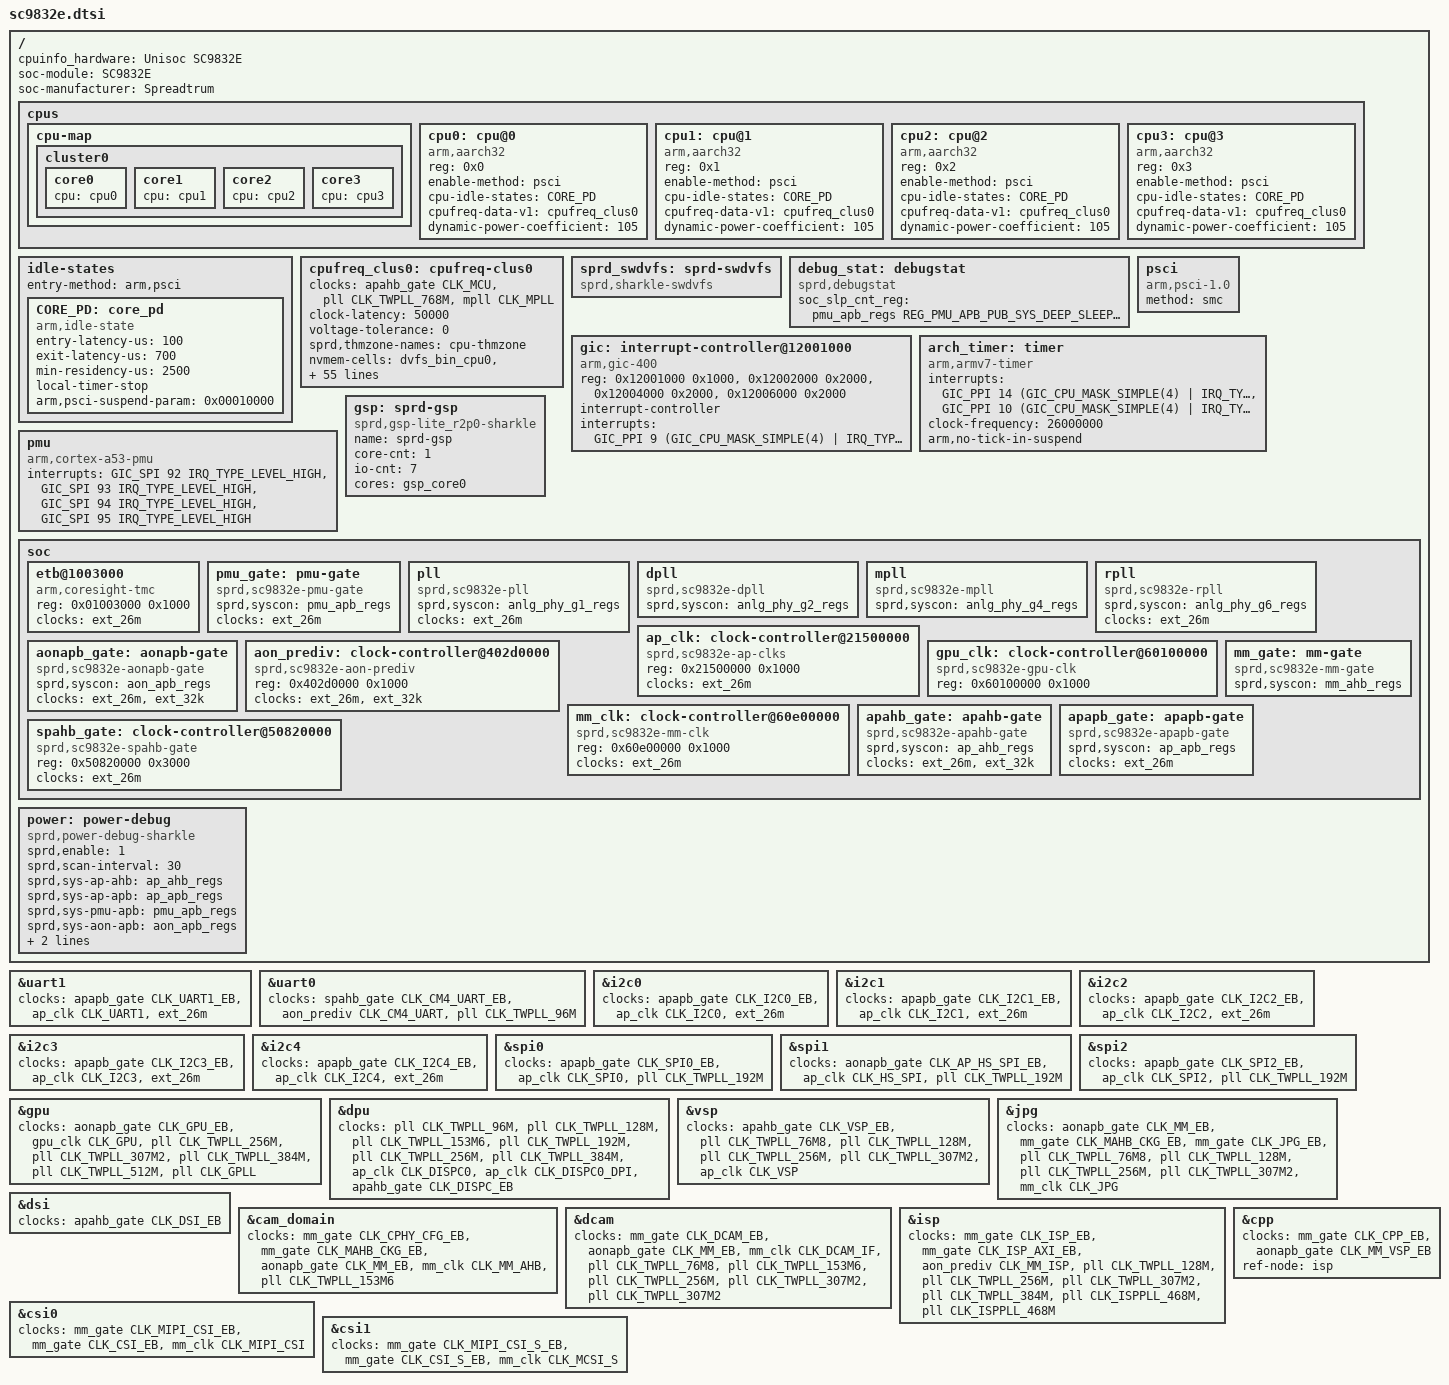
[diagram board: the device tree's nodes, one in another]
// SPDX-License-Identifier: GPL-2.0-only
/*
 * Spreadtrum SC9832e SoC DTS file
 *
 * Copyright (C) 2021, Spreadtrum Communications Inc.
 *
 * This file is licensed under a dual GPLv2 or X11 license.
 */
#include <dt-bindings/clock/sprd,sc9832e-clk.h>
#include "sharkle.dtsi"

/ {
	cpuinfo_hardware = "Unisoc SC9832E";
	soc-module = "SC9832E";
	soc-manufacturer = "Spreadtrum";

	cpus {
		#address-cells = <1>;
		#size-cells = <0>;

		cpu-map {
			cluster0 {
				core0 {
					cpu = <&cpu0>;
				};
				core1 {
					cpu = <&cpu1>;
				};
				core2 {
					cpu = <&cpu2>;
				};
				core3 {
					cpu = <&cpu3>;
				};
			};
		};


		cpu0: cpu@0 {
			device_type = "cpu";
			compatible = "arm,aarch32";
			reg = <0x0>;
			enable-method = "psci";
			cpu-idle-states = <&CORE_PD>;
			cpufreq-data-v1 = <&cpufreq_clus0>;
			dynamic-power-coefficient = <105>;
			#cooling-cells = <2>;
		};
		cpu1: cpu@1 {
			device_type = "cpu";
			compatible = "arm,aarch32";
			reg = <0x1>;
			enable-method = "psci";
			cpu-idle-states = <&CORE_PD>;
			cpufreq-data-v1 = <&cpufreq_clus0>;
			dynamic-power-coefficient = <105>;
			#cooling-cells = <2>;
		};
		cpu2: cpu@2 {
			device_type = "cpu";
			compatible = "arm,aarch32";
			reg = <0x2>;
			enable-method = "psci";
			cpu-idle-states = <&CORE_PD>;
			cpufreq-data-v1 = <&cpufreq_clus0>;
			dynamic-power-coefficient = <105>;
			#cooling-cells = <2>;
		};
		cpu3: cpu@3 {
			device_type = "cpu";
			compatible = "arm,aarch32";
			reg = <0x3>;
			enable-method = "psci";
			cpu-idle-states = <&CORE_PD>;
			cpufreq-data-v1 = <&cpufreq_clus0>;
			dynamic-power-coefficient = <105>;
			#cooling-cells = <2>;
		};
	};

	idle-states{
		entry-method = "arm,psci";
		CORE_PD: core_pd {
			compatible = "arm,idle-state";
			entry-latency-us = <100>;
			exit-latency-us = <700>;
			min-residency-us = <2500>;
			local-timer-stop;
			arm,psci-suspend-param = <0x00010000>;
		};
	};

	cpufreq_clus0: cpufreq-clus0 {
		clocks = <&apahb_gate CLK_MCU>,
			<&pll CLK_TWPLL_768M>,
			<&mpll CLK_MPLL>;
		clock-names = "core_clk",
			"low_freq_clk_parent",
			"high_freq_clk_parent";
		clock-latency = <50000>;
		voltage-tolerance = <0>;
		sprd,thmzone-names = "cpu-thmzone";
		nvmem-cells = <&dvfs_bin_cpu0>, <&dvfs_bin_low_volt_cpu0>;
		nvmem-cell-names = "dvfs_bin", "dvfs_bin_low_volt";
		sprd,cpufreq-temp-threshold = <65>;
		cpufreq-cluster-cpumask = <0xf>;
		sprd,ss-waferid-names =
			"T8F619_1","T8F619_2",
			"T8F619_3","T8F619_4",
			"T8F619_6","T8F619_7",
			"T8F619_8","T8F619_10",
			"T8F619_11","T8F619_12",
			"T8F619_13","T8F619_15",
			"T8F619_16","T8F619_18",
			"T8F619_19","T8F619_20",
			"T8F619_22","T8F619_23",
			"T8F619_24","T8F619_25",
			"T8F622_1","T8F622_2",
			"T8F622_3","T8F622_4",
			"T8F622_5","T8F622_6",
			"T8F801_1","T8F801_2",
			"T8F801_4","T8F801_3",
			"T9S964_1";
		operating-points = <
			/* kHz  uV */
			1400000 1150000
			1300000 1112500
			1100000 1034375
			 900000 953125
			 768000 900000>;
		operating-points-1-0 = <
			/* kHz	uV */
			/*1500000 1056250*/
			1400000	1021875
			1300000	 987500
			1100000	 918750
			 900000	 900000
			 768000	 900000>;
		operating-points-2-0 = <
			/* kHz	uV */
			/*1500000 1109375*/
			1400000	1071875
			1300000	1034375
			1100000	 959375
			 900000	 900000
			 768000	 900000>;
		operating-points-3-0 = <
			/* kHz	uV */
			1400000	1121875
			1300000	1081250
			1100000	1000000
			 900000	 921875
			 768000	 900000>;
		operating-points-4-0 = <
			/* kHz	uV */
			1400000	1150000
			1300000	1112500
			1100000	1034375
			 900000	 953125
			 768000	 900000>;
		operating-points-1-1 = <
			/* kHz	uV */
			/*1500000 1056250*/
			1400000	1021875
			1300000	 987500
			1100000	 918750
			 900000	 850000
			 768000	 850000>;
		operating-points-2-1 = <
			/* kHz	uV */
			/*1500000 1109375*/
			1400000	1071875
			1300000	1034375
			1100000	 959375
			 900000	 881250
			 768000	 850000>;
		operating-points-3-1 = <
			/* kHz	uV */
			1400000	1121875
			1300000	1081250
			1100000	1000000
			 900000	 921875
			 768000	 868750>;
		operating-points-4-1 = <
			/* kHz	uV */
			1400000	1150000
			1300000	1112500
			1100000	1034375
			 900000	 953125
			 768000	 900000>;
		operating-points-1-0-65 = <
			/* kHz	uV */
			/*1500000 1084375*/
			1400000	1043750
			1300000	1003125
			1100000	 921875
			 900000	 900000
			 768000	 900000>;
		operating-points-2-0-65 = <
			/* kHz	uV */
			/*1500000 1140625*/
			1400000	1096875
			1300000	1053125
			1100000	 965625
			 900000	 900000
			 768000	 900000>;
		operating-points-3-0-65 = <
			/* kHz	uV */
			1400000	1150000
			1300000	1106250
			1100000	1015625
			 900000	 925000
			 768000	 900000>;
		operating-points-4-0-65 = <
			/* kHz	uV */
			/*1400000 1181250*/
			1300000	1137500
			1100000	1050000
			 900000	 959375
			 768000	 900000>;
		operating-points-1-1-65 = <
			/* kHz	uV */
			/*1500000 1084375*/
			1400000	1043750
			1300000	1003125
			1100000	 921875
			 900000	 900000
			 768000	 900000>;
		operating-points-2-1-65 = <
			/* kHz	uV */
			/*1500000 1140625*/
			1400000	1096875
			1300000	1053125
			1100000	 965625
			 900000	 900000
			 768000	 900000>;
		operating-points-3-1-65 = <
			/* kHz	uV */
			1400000	1150000
			1300000	1106250
			1100000	1015625
			 900000	 925000
			 768000	 900000>;
		operating-points-4-1-65 = <
			/* kHz	uV */
			/*1400000 1181250*/
			1300000	1137500
			1100000	1050000
			 900000	 959375
			 768000	 900000>;
		operating-points-3 = <
			/* kHz	uV */
			1400000	1121875
			1300000	1081250
			1100000	1000000
			 900000	 921875
			 768000	 900000>;
		operating-points-4 = <
			/* kHz	uV */
			1400000	1150000
			1300000	1112500
			1100000	1034375
			 900000	 953125
			 768000	 900000>;
		operating-points-3-65 = <
			/* kHz	uV */
			1400000	1150000
			1300000	1106250
			1100000	1015625
			 900000	 925000
			 768000	 900000>;
		operating-points-4-65 = <
			/* kHz	uV */
			/*1400000 1181250*/
			1300000	1137500
			1100000	1050000
			 900000	 959375
			 768000	 900000>;
	};

	sprd_swdvfs: sprd-swdvfs {
		compatible = "sprd,sharkle-swdvfs";
	};

	debug_stat: debugstat {
		compatible = "sprd,debugstat";
		soc_slp_cnt_reg = <&pmu_apb_regs REG_PMU_APB_PUB_SYS_DEEP_SLEEP_CNT 0xff>;
	};

	psci {
		compatible = "arm,psci-1.0";
		method = "smc";
	};

	gic: interrupt-controller@12001000 {
		compatible = "arm,gic-400";
		reg = <0x12001000 0x1000>,
			<0x12002000 0x2000>,
			<0x12004000 0x2000>,
			<0x12006000 0x2000>;
		#interrupt-cells = <3>;
		interrupt-controller;
		interrupts = <GIC_PPI 9 (GIC_CPU_MASK_SIMPLE(4) | IRQ_TYPE_LEVEL_HIGH)>;
	};

	arch_timer: timer {
		compatible = "arm,armv7-timer";
		interrupts = <GIC_PPI 14 (GIC_CPU_MASK_SIMPLE(4) | IRQ_TYPE_LEVEL_LOW)>,
			     <GIC_PPI 10 (GIC_CPU_MASK_SIMPLE(4) | IRQ_TYPE_LEVEL_LOW)>;
		clock-frequency = <26000000>;
		arm,no-tick-in-suspend;
	};

	pmu {
		compatible = "arm,cortex-a53-pmu";
		interrupts = <GIC_SPI 92 IRQ_TYPE_LEVEL_HIGH>,
				<GIC_SPI 93 IRQ_TYPE_LEVEL_HIGH>,
				<GIC_SPI 94 IRQ_TYPE_LEVEL_HIGH>,
				<GIC_SPI 95 IRQ_TYPE_LEVEL_HIGH>;
	};

	gsp: sprd-gsp {
		compatible = "sprd,gsp-lite_r2p0-sharkle";
		name = "sprd-gsp";
		core-cnt = <1>;
		io-cnt = <7>;
		cores = <&gsp_core0>;
	};

	soc {
		etb@1003000 {
			compatible = "arm,coresight-tmc", "arm,primecell";
			reg = <0x01003000 0x1000>;
			clocks = <&ext_26m>;
			clock-names = "apb_pclk";
		};

		pmu_gate: pmu-gate {
			compatible = "sprd,sc9832e-pmu-gate";
			sprd,syscon = <&pmu_apb_regs>; /* 0x402b0000 */
			clock-names = "ext-26m";
			clocks = <&ext_26m>;
			#clock-cells = <1>;
		};

		pll: pll {
			compatible = "sprd,sc9832e-pll";
			sprd,syscon = <&anlg_phy_g1_regs>; /* 0x403c0000 */
			clock-names = "ext-26m";
			clocks = <&ext_26m>;
			#clock-cells = <1>;
		};

		dpll: dpll {
			compatible = "sprd,sc9832e-dpll";
			sprd,syscon = <&anlg_phy_g2_regs>; /* 0x403d0000 */
			#clock-cells = <1>;
		};

		mpll: mpll {
			compatible = "sprd,sc9832e-mpll";
			sprd,syscon = <&anlg_phy_g4_regs>; /* 0x403f0000 */
			#clock-cells = <1>;
		};

		rpll: rpll {
			compatible = "sprd,sc9832e-rpll";
			sprd,syscon = <&anlg_phy_g6_regs>; /* 0x40410000 */
			clock-names = "ext-26m";
			clocks = <&ext_26m>;
			#clock-cells = <1>;
		};

		ap_clk: clock-controller@21500000 {
			compatible = "sprd,sc9832e-ap-clks"; /* 0x21500000 */
			reg = <0x21500000 0x1000>;
			clock-names = "ext-26m";
			clocks = <&ext_26m>;
			#clock-cells = <1>;
		};

		aonapb_gate: aonapb-gate {
			compatible = "sprd,sc9832e-aonapb-gate"; /* 0x402e0000 */
			sprd,syscon = <&aon_apb_regs>;
			clock-names = "ext-26m", "ext-32k";
			clocks = <&ext_26m>, <&ext_32k>;
			#clock-cells = <1>;
		};

		aon_prediv: clock-controller@402d0000 {
			compatible = "sprd,sc9832e-aon-prediv"; /* 0x402d0000 */
			reg = <0x402d0000 0x1000>;
			clock-names = "ext-26m", "ext-32k";
			clocks = <&ext_26m>, <&ext_32k>;
			#clock-cells = <1>;
		};

		gpu_clk: clock-controller@60100000 {
			compatible = "sprd,sc9832e-gpu-clk";
			reg = <0x60100000 0x1000>; /* 0x60100000 */
			#clock-cells = <1>;
		};

		mm_clk: clock-controller@60e00000 {
			compatible = "sprd,sc9832e-mm-clk";
			reg = <0x60e00000 0x1000>; /* 0x60e00000 */
			clock-names = "ext-26m";
			clocks = <&ext_26m>;
			#clock-cells = <1>;
		};

		mm_gate: mm-gate {
			compatible = "sprd,sc9832e-mm-gate";
			sprd,syscon = <&mm_ahb_regs>; /* 0x60d00000 */
			#clock-cells = <1>;
		};

		apahb_gate: apahb-gate {
			compatible = "sprd,sc9832e-apahb-gate";
			sprd,syscon = <&ap_ahb_regs>; /* 0x20e00000 */
			clock-names = "ext-26m", "ext-32k";
			clocks = <&ext_26m>, <&ext_32k>;
			#clock-cells = <1>;
		};

		apapb_gate: apapb-gate {
			compatible = "sprd,sc9832e-apapb-gate";
			sprd,syscon = <&ap_apb_regs>; /* 0x71300000 */
			clock-names = "ext-26m";
			clocks = <&ext_26m>;
			#clock-cells = <1>;
			#reset-cells = <1>;
		};

		spahb_gate: clock-controller@50820000 {
			compatible = "sprd,sc9832e-spahb-gate";
			reg = <0x50820000 0x3000>; /* 0x50820000 */
			clock-names = "ext-26m";
			clocks = <&ext_26m>;
			#clock-cells = <1>;
		};
	};

	power: power-debug {
		compatible = "sprd,power-debug-sharkle";

		sprd,enable = <1>;
		sprd,scan-interval = <30>;

		sprd,sys-ap-ahb = <&ap_ahb_regs>;
		sprd,sys-ap-apb = <&ap_apb_regs>;
		sprd,sys-pmu-apb = <&pmu_apb_regs>;
		sprd,sys-aon-apb = <&aon_apb_regs>;
		sprd,sys-ap-intc = <&intc0_regs &intc1_regs
				&intc2_regs &intc3_regs>;
	};
};

&uart1 {
	clock-names = "enable", "uart", "source";
	clocks = <&apapb_gate CLK_UART1_EB>,
		 <&ap_clk CLK_UART1>, <&ext_26m>;
};

&uart0 {
	clock-names = "enable", "uart", "source";
	clocks = <&spahb_gate CLK_CM4_UART_EB>,
		 <&aon_prediv CLK_CM4_UART>, <&pll CLK_TWPLL_96M>;
};

&i2c0 {
	clock-names ="enable", "i2c", "source";
	clocks = <&apapb_gate CLK_I2C0_EB>,
	<&ap_clk CLK_I2C0>, <&ext_26m>;
};

&i2c1 {
	clock-names ="enable", "i2c", "source";
	clocks = <&apapb_gate CLK_I2C1_EB>,
	<&ap_clk CLK_I2C1>, <&ext_26m>;
};

&i2c2 {
	clock-names ="enable", "i2c", "source";
	clocks = <&apapb_gate CLK_I2C2_EB>,
	<&ap_clk CLK_I2C2>, <&ext_26m>;
};

&i2c3 {
	clock-names ="enable", "i2c", "source";
	clocks = <&apapb_gate CLK_I2C3_EB>,
	<&ap_clk CLK_I2C3>, <&ext_26m>;
};

&i2c4 {
	clock-names ="enable", "i2c", "source";
	clocks = <&apapb_gate CLK_I2C4_EB>,
	<&ap_clk CLK_I2C4>, <&ext_26m>;
};


&spi0 {
	clock-names ="enable", "spi", "source";
	clocks = <&apapb_gate CLK_SPI0_EB>,
	<&ap_clk CLK_SPI0>, <&pll CLK_TWPLL_192M>;
};

&spi1 {
	clock-names ="enable", "spi", "source";
	clocks = <&aonapb_gate CLK_AP_HS_SPI_EB>,
	<&ap_clk CLK_HS_SPI>, <&pll CLK_TWPLL_192M>;
};

&spi2 {
	clock-names ="enable", "spi", "source";
	clocks = <&apapb_gate CLK_SPI2_EB>,
	<&ap_clk CLK_SPI2>, <&pll CLK_TWPLL_192M>;
};

&gpu {
	clocks = <&aonapb_gate CLK_GPU_EB>,
		<&gpu_clk CLK_GPU>,
		<&pll CLK_TWPLL_256M>, <&pll CLK_TWPLL_307M2>,
		<&pll CLK_TWPLL_384M>, <&pll CLK_TWPLL_512M>,
		<&pll CLK_GPLL>;
};

&dpu {
	clock-names = "clk_src_96m",
			"clk_src_128m",
			"clk_src_153m6",
			"clk_src_192m",
			"clk_src_256m",
			"clk_src_384m",
			"clk_dpu_core",
			"clk_dpu_dpi",
			"clk_ap_ahb_disp_eb";

	clocks = <&pll CLK_TWPLL_96M>,
		<&pll CLK_TWPLL_128M>,
		<&pll CLK_TWPLL_153M6>,
		<&pll CLK_TWPLL_192M>,
		<&pll CLK_TWPLL_256M>,
		<&pll CLK_TWPLL_384M>,
		<&ap_clk CLK_DISPC0>,
		<&ap_clk CLK_DISPC0_DPI>,
		<&apahb_gate CLK_DISPC_EB>;
};

&vsp {
	clock-names = "clk_ahb_gate_vsp_eb",
			"clk_src_76m8",
			"clk_src_128m",
			"clk_src_256m",
			"clk_src_307m2",
			"clk_vsp";
	clocks = <&apahb_gate CLK_VSP_EB>,
		<&pll CLK_TWPLL_76M8>,
		<&pll CLK_TWPLL_128M>,
		<&pll CLK_TWPLL_256M>,
		<&pll CLK_TWPLL_307M2>,
		<&ap_clk CLK_VSP>;
};

&jpg {
	clock-names =
			"jpg_domain_eb",
			"jpg_ckg_eb",
			"jpg_dev_eb",
			"clk_src_76m8",
			"clk_src_128m",
			"clk_src_256m",
			"clk_src_307m2",
			"jpg_clk";
	clocks = <&aonapb_gate CLK_MM_EB>,
		<&mm_gate CLK_MAHB_CKG_EB>,
		<&mm_gate CLK_JPG_EB>,
		<&pll CLK_TWPLL_76M8>,
		<&pll CLK_TWPLL_128M>,
		<&pll CLK_TWPLL_256M>,
		<&pll CLK_TWPLL_307M2>,
		<&mm_clk CLK_JPG>;
};

&dsi {
	clock-names = "clk_ap_ahb_dsi_eb";
	clocks = <&apahb_gate CLK_DSI_EB>;
};

&cam_domain {
	clock-names = "clk_cphy_cfg_gate_eb",
				"clk_gate_eb",
				"clk_mm_eb",
				"clk_mm_ahb",
				"clk_mm_ahb_parent";
	clocks = <&mm_gate CLK_CPHY_CFG_EB>,
				<&mm_gate CLK_MAHB_CKG_EB>,
				<&aonapb_gate CLK_MM_EB>,
				<&mm_clk CLK_MM_AHB>,
				<&pll CLK_TWPLL_153M6>;
};

&dcam {
	clock-names = "dcam_eb",
			"clk_mm_eb",
			"dcam_clk",
			"dcam_clk_76m8",
			"dcam_clk_153m6",
			"dcam_clk_256m",
			"dcam_clk_307m2",
			"dcam_clk_parent";
	clocks = <&mm_gate CLK_DCAM_EB>,
		<&aonapb_gate CLK_MM_EB>,
		<&mm_clk CLK_DCAM_IF>,
		<&pll CLK_TWPLL_76M8>,
		<&pll CLK_TWPLL_153M6>,
		<&pll CLK_TWPLL_256M>,
		<&pll CLK_TWPLL_307M2>,
		<&pll CLK_TWPLL_307M2>;
};

&isp {
	clock-names = "isp_eb", "isp_axi_eb",
			"isp_clk",
			"isp_clk_128m",
			"isp_clk_256m",
			"isp_clk_307m2",
			"isp_clk_384m",
			"isp_clk_468m",
			"isp_clk_parent";
	clocks = <&mm_gate CLK_ISP_EB>,
		<&mm_gate CLK_ISP_AXI_EB>,
		<&aon_prediv CLK_MM_ISP>,
		<&pll CLK_TWPLL_128M>,
		<&pll CLK_TWPLL_256M>,
		<&pll CLK_TWPLL_307M2>,
		<&pll CLK_TWPLL_384M>,
		<&pll CLK_ISPPLL_468M>,
		<&pll CLK_ISPPLL_468M>;
};

&cpp {
	clock-names = "cpp_eb",
			"cpp_axi_eb";
	clocks = <&mm_gate CLK_CPP_EB>,
		<&aonapb_gate CLK_MM_VSP_EB>;
	/* hw: cpp, isp use the same clk */
	ref-node = <&isp>;
};

&csi0 {
	clock-names = "clk_mipi_csi_gate_eb",
			"clk_csi_eb",
			"clk_csi_from";
	clocks = <&mm_gate CLK_MIPI_CSI_EB>,
		<&mm_gate CLK_CSI_EB>,
		<&mm_clk CLK_MIPI_CSI>;
};

&csi1 {
	clock-names = "clk_mipi_csi_gate_eb",
			"clk_csi_eb",
			"clk_csi_from";
	clocks = <&mm_gate CLK_MIPI_CSI_S_EB>,
		<&mm_gate CLK_CSI_S_EB>,
		<&mm_clk CLK_MCSI_S>;
};

